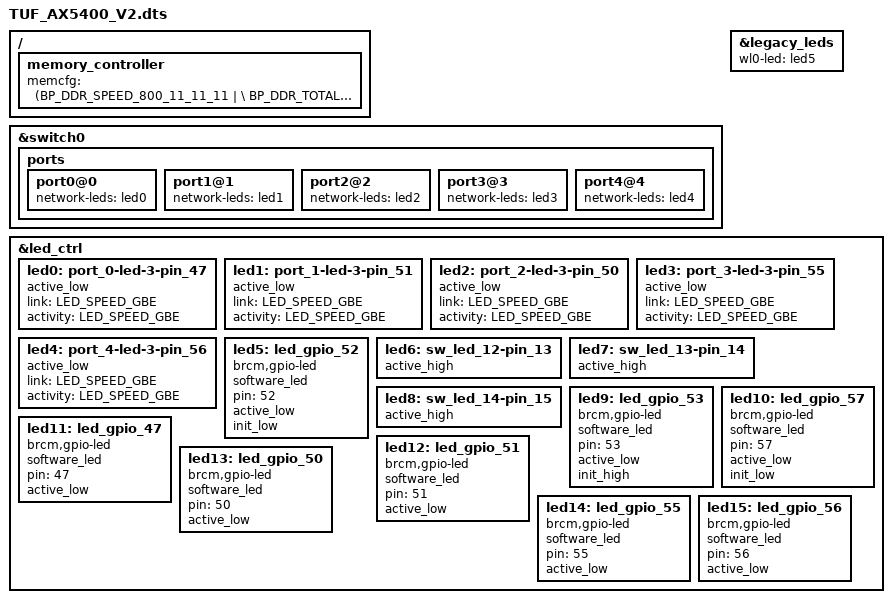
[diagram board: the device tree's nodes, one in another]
#include "63178.dtsi"

/ {
    memory_controller {
        memcfg = <(BP_DDR_SPEED_800_11_11_11 | \
                   BP_DDR_TOTAL_SIZE_512MB   | \
                   BP_DDR_DEVICE_WIDTH_16    | \
                   BP_DDR_TOTAL_WIDTH_16BIT  | \
                   BP_DDR_63178_DEFAULT)>;
    };
#if 0
	buttons {
		compatible = "brcm,buttons";
		reset_button {
			ext_irq = <&bca_extintr 0 BCA_GPIO_ACTIVE_LOW (BCA_EXTINTR_TYPE_LOW_LEVEL | BCA_EXTINTR_TYPE_SENSE_EDGE)>;
			press {
				print = "Button Press -- Hold for 5s to do restore to default";
			};
			hold {
				rst_to_dflt = <5>;
			};
			release {
				reset = <0>;
			};	
		};
		ses_button {
			ext_irq = <&bca_extintr 21 BCA_GPIO_ACTIVE_LOW (BCA_EXTINTR_TYPE_LOW_LEVEL | BCA_EXTINTR_TYPE_SENSE_EDGE)>;
			release {
				ses_short_period = <0>;
				ses_long_period = <3>;
			};
		};
	};
#endif
};

&switch0 {
	ports {
		port0@0 {
			status = "okay";
			network-leds = <&led0>;
		};

		port1@1 {
			status = "okay";
			network-leds = <&led1>;
		};

		port2@2 {
			status = "okay";
			network-leds = <&led2>;
		};

		port3@3 {
			status = "okay";
			network-leds = <&led3>;
		};

		port4@4 {
			status = "okay";
			network-leds = <&led4>;
		};
	};
};

&legacy_leds {
	wl0-led = <&led5>;
};

&led_ctrl {
	status = "okay";

	/* LAN0 ~ LAN3 LED */
	led0: port_0-led-3-pin_47 {
		active_low;
		link = <LED_SPEED_GBE>;
		activity = <LED_SPEED_GBE>;
		status = "okay";
	};
	led1: port_1-led-3-pin_51 {
		active_low;
		link = <LED_SPEED_GBE>;
		activity = <LED_SPEED_GBE>;
		status = "okay";
	};
	led2: port_2-led-3-pin_50 {
		active_low;
		link = <LED_SPEED_GBE>;
		activity = <LED_SPEED_GBE>;
		status = "okay";
	};
	led3: port_3-led-3-pin_55 {
		active_low;
		link = <LED_SPEED_GBE>;
		activity = <LED_SPEED_GBE>;
		status = "okay";
	};
	/* WAN LED */
	led4: port_4-led-3-pin_56 {
		active_low;
		link = <LED_SPEED_GBE>;
		activity = <LED_SPEED_GBE>;
		status = "okay";
	};
#if 0
	/* 2.4G WIFI LED */
		led5: sw_led_28-pin_52 {
		active_low;
		status = "okay";
	};
#else
	/* WLAN_2G_ACT */
	led5:led_gpio_52 {
		compatible = "brcm,gpio-led";
		software_led;
		pin = <52>;
		active_low;
		init_low;
	};
#endif
#if 0
	/* TUF LOGO LED1 */
	led6:led_gpio_13 {
		compatible = "brcm,gpio-led";
		software_led;
		pin = <13>;
		active_low;
		init_high;
	};
	/* TUF LOGO LED2 */
	led7:led_gpio_14 {
		compatible = "brcm,gpio-led";
		software_led;
		pin = <14>;
		active_low;
		init_high;
	};
	/* TUF LOGO LED3 */
		led8:led_gpio_15 {
		compatible = "brcm,gpio-led";
		software_led;
		pin = <15>;
		active_low;
		init_high;
	};
#endif
	/* LED Group RED */
	led6: sw_led_12-pin_13 {
		active_high;
		status = "okay";
	};

	/* LED Group GREEN */
	led7: sw_led_13-pin_14 {
		active_high;
		status = "okay";
	};

	/* LED Group BLUE */
	led8: sw_led_14-pin_15 {
		active_high;
		status = "okay";
	};

	/* WAN LED(RED) */
	led9:led_gpio_53 {
		compatible = "brcm,gpio-led";
		software_led;
		pin = <53>;
		active_low;
		init_high;
	};

	/* Power on/off LED */
	led10:led_gpio_57 {
		compatible = "brcm,gpio-led";
		software_led;
		pin = <57>;
		active_low;
		init_low;
	};

	/* LAN0 LED */
	led11:led_gpio_47 {
		compatible = "brcm,gpio-led";
		software_led;
		pin = <47>;
		active_low;
	};

	/* LAN1 LED */
	led12:led_gpio_51 {
		compatible = "brcm,gpio-led";
		software_led;
		pin = <51>;
		active_low;
	};
	/* LAN2 LED */
	led13:led_gpio_50 {
		compatible = "brcm,gpio-led";
		software_led;
		pin = <50>;
		active_low;
	};
	/* LAN3 LED */
	led14:led_gpio_55 {
		compatible = "brcm,gpio-led";
		software_led;
		pin = <55>;
		active_low;
	};

	/* WAN LED */
	led15:led_gpio_56 {
		compatible = "brcm,gpio-led";
		software_led;
		pin = <56>;
		active_low;
	};
};
